AUTOSAR XML (schema 4.0)
package /primatec/light/lceComManager
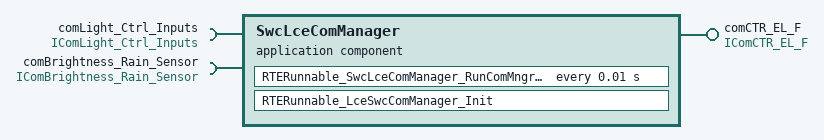
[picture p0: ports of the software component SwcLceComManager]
  application sw component type SwcLceComManager
    provide port comCTR_EL_F: provided-interface=IComCTR_EL_F
    require port comLight_Ctrl_Inputs: required-interface=IComLight_Ctrl_Inputs
    require port comBrightness_Rain_Sensor: required-interface=IComBrightness_Rain_Sensor
    behavior SwcLceComManager_DefaultBehavior
      timing event periodRunnable_LceComManager10ms: start-on-event=RTERunnable_SwcLceComManager_RunComMngr_10msTask, period=0.01
      runnable RTERunnable_LceSwcComManager_Init: symbol=RTERunnable_SwcLceComManager_Init
      runnable RTERunnable_SwcLceComManager_RunComMngr_10msTask: can-be-invoked-concurrently=true
        data-receive-point-by-arguments:
          access DRPA_comLight_Ctrl_Inputs_ST_LP_LIN: accessed-variable=comLight_Ctrl_Inputs.ST_LP_LIN
          access DRPA_comBrightness_Rain_Sensor_ST_RB_LIN: accessed-variable=comBrightness_Rain_Sensor.ST_RB_LIN
        data-send-points:
          access DRPA_comCTR_EL_F_CTR_FN_DR: accessed-variable=comCTR_EL_F.CTR_FN_DR
          access DRPA_comCTR_EL_F_CTR_FN_POS: accessed-variable=comCTR_EL_F.CTR_FN_POS
          access DRPA_comCTR_EL_F_CTR_FN_PAR: accessed-variable=comCTR_EL_F.CTR_FN_PAR
